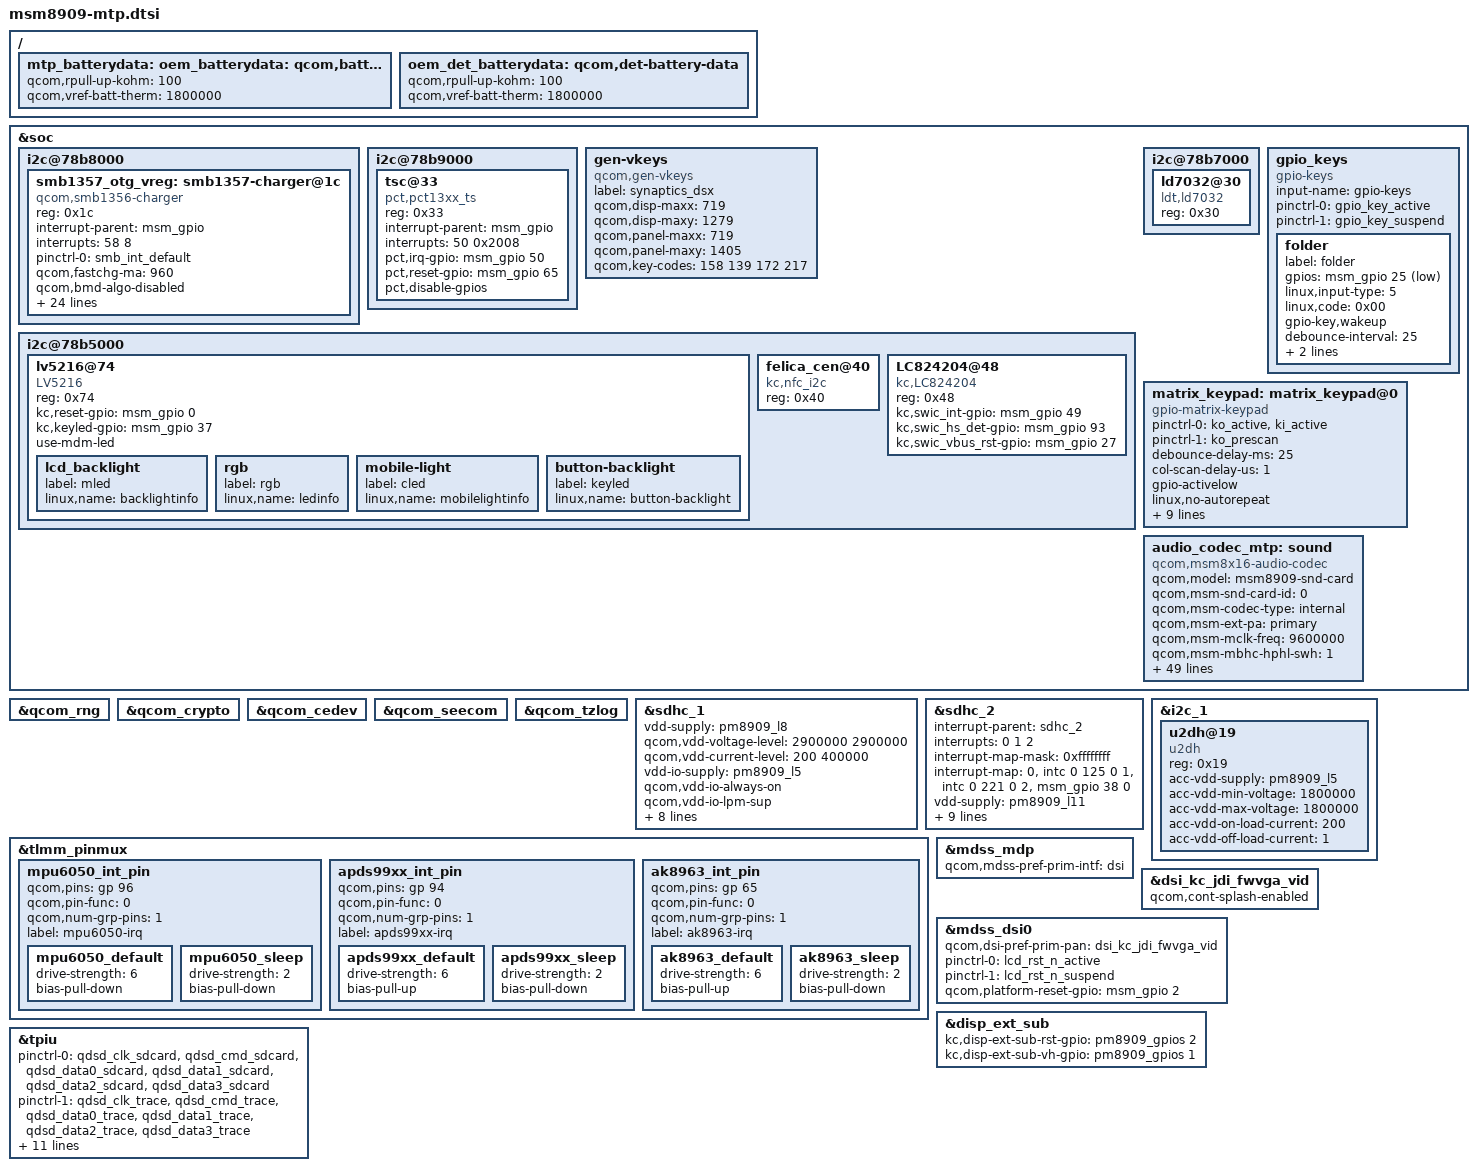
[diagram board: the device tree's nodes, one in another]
/* Copyright (c) 2014-2015, The Linux Foundation. All rights reserved.
 *
 * This program is free software; you can redistribute it and/or modify
 * it under the terms of the GNU General Public License version 2 and
 * only version 2 as published by the Free Software Foundation.
 *
 * This program is distributed in the hope that it will be useful,
 * but WITHOUT ANY WARRANTY; without even the implied warranty of
 * MERCHANTABILITY or FITNESS FOR A PARTICULAR PURPOSE.  See the
 * GNU General Public License for more details.
 */
/*
 * This software is contributed or developed by KYOCERA Corporation.
 * (C) 2016 KYOCERA Corporation
 */

#include "msm8909.dtsi"
#include "msm8909-pinctrl.dtsi"
#include "msm8909-camera-sensor-mtp.dtsi"
#include "msm8909-pm8916.dtsi"

&soc {
	/*
	 * DT node to add support for SMB135x charger and integrate
	 * with VM-BMS.
	 */
	i2c@78b8000 {
		smb1357_otg_vreg: smb1357-charger@1c {
			compatible = "qcom,smb1356-charger";
			reg = <0x1c>;
			interrupt-parent = <&msm_gpio>;
			interrupts = <58 8>;
			pinctrl-names = "default";
			pinctrl-0 = <&smb_int_default>;

			qcom,fastchg-ma = <960>;
			qcom,bmd-algo-disabled;
			qcom,float-voltage-mv = <4300>;
			qcom,charging-timeout = <768>;
			qcom,recharge-thresh-mv = <200>;
			qcom,thermal-mitigation = <960 540 180 0>;

			qcom,bms-psy-name = "bms";

			/*
			 * JEITA
			 */
			qcom,gamma-setting = <2 3 0 3>;

			/*
			 * Enable SMB1357 based charging termination as BMS
			 * controls charging.
			 */
			qcom,iterm-ma = <100>;
			

			/*
			 * Disable charge inhibit feature to start chargin on
			 * charger insertion independent of battery voltage.
			 */
			qcom,inhibit-disabled;

			/* BMS is controlling charging/re-charge */
			//	qcom,bms-controlled-charging;

			/*
			 * To enable charger node:
			 * set status = "ok" and
			 * add 'qcom,use-external-charger' to pm8909_chg node
			 */
			status = "ok";

			/*
			 * For DC charging support
			 */
			qcom,dc-psy-type = "Mains";
			qcom,dc-psy-ma = <960>;

			/*
			 * SW_JEITA
			 */
			qcom,soft-vfloat-comp-disabled;
			qcom,soft-current-comp-disabled;
			qcom,chg-vadc = <&pm8916_vadc>;
			qcom,chg-adc_tm = <&pm8916_adc_tm>;
			qcom,hot-bat-decidegc = <500>;
			qcom,cold-bat-decidegc = <0>;
			qcom,bat-present-decidegc = <300>;
			qcom,warm-bat-decidegc = <450>;
			qcom,cool-bat-decidegc = <100>;
			qcom,warm-bat-ma = <420>;
			qcom,cool-bat-ma = <420>;
			qcom,warm-bat-mv = <4200>;
			qcom,cool-bat-mv = <4200>;

			/*
			 * Voltage at the time of battery deterioration
			 */
			oem,deterioration-vfloat-mv = <4200>;
		};
	};

	i2c@78b9000 { /* BLSP1 QUP5 */
		tsc@33 {
			compatible = "pct,pct13xx_ts";
			reg = <0x33>;
			interrupt-parent = <&msm_gpio>;
			interrupts = <50 0x2008>;
			pct,irq-gpio = <&msm_gpio 50 0x2008>;
			pct,reset-gpio = <&msm_gpio 65 0x0>;
			pct,disable-gpios;
		};
	};

	gen-vkeys {
		compatible = "qcom,gen-vkeys";
		label = "synaptics_dsx";
		qcom,disp-maxx = <719>;
		qcom,disp-maxy = <1279>;
		qcom,panel-maxx = <719>;
		qcom,panel-maxy = <1405>;
		qcom,key-codes = <158 139 172 217>;
	};

//	i2c@78b6000 { /* BLSP1 QUP2 */
//		nfc-nci@e {
//			compatible = "qcom,nfc-nci";
//			reg = <0x0e>;
//			qcom,irq-gpio = <&msm_gpio 21 0x00>;
//			qcom,dis-gpio = <&msm_gpio 20 0x00>;
//			qcom,clk-src = "BBCLK2";
//			interrupt-parent = <&msm_gpio>;
//			interrupts = <21 0>;
//			interrupt-names = "nfc_irq";
//			pinctrl-names = "nfc_active","nfc_suspend";
//			pinctrl-0 = <&nfc_int_active &nfc_disable_active>;
//			pinctrl-1 = <&nfc_int_suspend &nfc_disable_suspend>;
//			clocks = <&clock_rpm clk_bb_clk2_pin>;
//			clock-names = "ref_clk";
//		};
//
//		nq@2b {
//			compatible = "qcom,nq-nci";
//			reg = <0x2b>;
//			qcom,nq-irq = <&msm_gpio 21 0x00>;
//			qcom,nq-ven = <&msm_gpio 20 0x00>;
//			qcom,nq-firm = <&msm_gpio 45 0x00>;
//			qcom,clk-src = "BBCLK2";
//			interrupt-parent = <&msm_gpio>;
//			interrupts = <21 0>;
//			interrupt-names = "nfc_irq";
//			pinctrl-names = "nfc_active","nfc_suspend";
//			pinctrl-0 = <&nfc_int_active &nfc_disable_active>;
//			pinctrl-1 = <&nfc_int_suspend &nfc_disable_suspend>;
//			clocks = <&clock_rpm clk_bb_clk2_pin>;
//			clock-names = "ref_clk";
//			};
//	};

	i2c@78b5000 {
		lv5216@74 {
			compatible = "LV5216";
			reg = <0x74>;
			kc,reset-gpio = <&msm_gpio 0 0x00>;
			kc,keyled-gpio = <&msm_gpio 37 0x00>;
			use-mdm-led;
			lcd_backlight {
				label = "mled";
				linux,name = "backlightinfo";
			};
			rgb {
				label = "rgb";
				linux,name = "ledinfo";
			};
			mobile-light {
				label = "cled";
				linux,name = "mobilelightinfo";
			};
			button-backlight {
				label = "keyled";
				linux,name = "button-backlight";
			};
		};
	};
	i2c@78b5000 {
		felica_cen@40 {
			status = "okay";
			compatible = "kc,nfc_i2c";
			reg = <0x40>;
		};
	};

	i2c@78b5000 {
		LC824204@48 {
			status = "okay";
			compatible = "kc,LC824204";
			reg = <0x48>;
			kc,swic_int-gpio = <&msm_gpio 49 0>;
			kc,swic_hs_det-gpio = <&msm_gpio 93 0>;
			kc,swic_vbus_rst-gpio = <&msm_gpio 27 0>;
		};
	};

	i2c@78b7000 {
		ld7032@30 {
			compatible = "ldt,ld7032";
			reg = <0x30>;
		};
	};

	gpio_keys {
		compatible = "gpio-keys";
		input-name = "gpio-keys";
		pinctrl-names = "tlmm_gpio_key_active","tlmm_gpio_key_suspend";
		pinctrl-0 = <&gpio_key_active>;
		pinctrl-1 = <&gpio_key_suspend>;

		//camera_focus {
		//	label = "camera_focus";
		//	gpios = <&msm_gpio 91 0x1>;
		//	linux,input-type = <1>;
		//	linux,code = <0x210>;
		//	gpio-key,wakeup;
		//	debounce-interval = <15>;
		//};

		//camera_snapshot {
		//	label = "camera_snapshot";
		//	gpios = <&msm_gpio 92 0x1>;
		//	linux,input-type = <1>;
		//	linux,code = <0x2fe>;
		//	gpio-key,wakeup;
		//	debounce-interval = <15>;
		//};

		//vol_up {
		//	label = "volume_up";
		//	gpios = <&msm_gpio 90 0x1>;
		//	linux,input-type = <1>;
		//	linux,code = <115>;
		//	gpio-key,wakeup;
		//	debounce-interval = <15>;
		//};

		folder {
			label = "folder";
			gpios =  <&msm_gpio 25 0x1>;
			linux,input-type = <5>;
			linux,code = <0x00>;
			gpio-key,wakeup;
			debounce-interval = <25>;
            on_chattering_num  = <1>;
            off_chattering_num = <1>;
		};

	};

	matrix_keypad: matrix_keypad@0 {
		compatible = "gpio-matrix-keypad";
		pinctrl-names = "matrix_keypad_active","matrix_keypad_prescan";
		pinctrl-0 = <&ko_active &ki_active>;
		pinctrl-1 = <&ko_prescan>;
		debounce-delay-ms = <25>;
		col-scan-delay-us = <1>;
		gpio-activelow;
		linux,no-autorepeat;
		linux,wakeup;

		row-gpios = <
			&msm_gpio 94 0
			&msm_gpio 95 0
			&msm_gpio 96 0
			&msm_gpio 97 0
			&msm_gpio 98 0
			&msm_gpio 91 0
		>;

		col-gpios = <
			&msm_gpio 16 0
			&msm_gpio 17 0
			&msm_gpio 34 0
			&msm_gpio 57 0
			&msm_gpio 92 0
			&msm_gpio  3 0
			&msm_gpio 28 0
			&msm_gpio 33 0
		>;

		linux,keymap = <
			0x00000002	/* KEY_1 [2] */
			0x00010005	/* KEY_4 [5] */
			0x00020008	/* KEY_7 [8] */
			0x00030037	/* KEY_KPASTERISK [55]*/
			0x0004003E	/* KEY_F4 [62] */
			0x01000003	/* KEY_2 [3] */
			0x01010006	/* KEY_5 [6] */
			0x01020009	/* KEY_8 [9] */
			0x0103000b	/* KEY_0 [11]*/
			0x0104003d	/* KEY_F3 [61] */
			0x02000004	/* KEY_3 [4] */
			0x02010007	/* KEY_6 [7] */
			0x0202000a	/* KEY_9 [10] */
			0x020300FD	/* KEY_SHARP [253] */
			0x02040163	/* KEY_CLEAR [0x163] */
			0x0305001C	/* KEY_ENTER [28] */
			0x03060067	/* KEY_UP [103] */
			0x0307006A	/* KEY_RIGHT [106] */
			0x04060069	/* KEY_LEFT [105] */
			0x0407006C	/* KEY_DOWN [108] */
			0x05000041	/* KEY_F7 [65] */
			0x0501003F	/* KEY_F5 [63] */
			0x05020040	/* KEY_F6 [64] */
			0x0503003B	/* KEY_F1 [59] */
			0x050400E7	/* KEY_SEND [231] */
			0x0505003C	/* KEY_F2 [60] */
		>;
	};

	audio_codec_mtp: sound {
		compatible = "qcom,msm8x16-audio-codec";
		qcom,model = "msm8909-snd-card";
		qcom,msm-snd-card-id = <0>;
		qcom,msm-codec-type = "internal";
		qcom,msm-ext-pa = "primary";
		qcom,msm-mclk-freq = <9600000>;
		qcom,msm-mbhc-hphl-swh = <1>;
		qcom,msm-mbhc-gnd-swh = <0>;
		qcom,msm-hs-micbias-type = "internal";
		qcom,msm-micbias1-ext-cap;
		qcom,audio-routing =
			"RX_BIAS", "MCLK",
			"SPK_RX_BIAS", "MCLK",
			"INT_LDO_H", "MCLK",
            "Rcv amp", "EAR",
			"MIC BIAS External", "Handset Mic",
			"MIC BIAS Internal2", "Headset Mic",
			"MIC BIAS External", "Secondary Mic",
			"AMIC1", "MIC BIAS External",
			"AMIC2", "MIC BIAS Internal2",
			"AMIC3", "MIC BIAS External";
		pinctrl-names = "cdc_lines_act",
				"cdc_lines_sus",
				"cross_conn_det_act",
				"cross_conn_det_sus";
		pinctrl-0 = <&cdc_pdm_lines_act>;
		pinctrl-1 = <&cdc_pdm_lines_sus>;
		pinctrl-2 = <&cross_conn_det_act>;
		pinctrl-3 = <&cross_conn_det_sus>;
//		qcom,cdc-us-euro-gpios = <&msm_gpio 97 0>;
		asoc-platform = <&pcm0>, <&pcm1>, <&voip>, <&voice>,
				<&loopback>, <&compress>, <&hostless>,
				<&afe>, <&lsm>, <&routing>, <&lpa>,
				<&voice_svc>;
		asoc-platform-names = "msm-pcm-dsp.0", "msm-pcm-dsp.1",
				"msm-voip-dsp", "msm-pcm-voice", "msm-pcm-loopback",
				"msm-compress-dsp", "msm-pcm-hostless", "msm-pcm-afe",
				"msm-lsm-client", "msm-pcm-routing", "msm-pcm-lpa",
				"msm-voice-svc";
		asoc-cpu = <&dai_pri_auxpcm>, <&dai_hdmi>,
				<&dai_mi2s0>, <&dai_mi2s1>, <&dai_mi2s2>, <&dai_mi2s3>,
				<&sb_0_rx>, <&sb_0_tx>, <&sb_1_rx>, <&sb_1_tx>,
				<&sb_3_rx>, <&sb_3_tx>, <&sb_4_rx>, <&sb_4_tx>,
				<&bt_sco_rx>, <&bt_sco_tx>, <&int_fm_rx>, <&int_fm_tx>,
				<&afe_pcm_rx>, <&afe_pcm_tx>, <&afe_proxy_rx>, <&afe_proxy_tx>,
				<&incall_record_rx>, <&incall_record_tx>, <&incall_music_rx>,
				<&incall_music_2_rx>;
		asoc-cpu-names = "msm-dai-q6-auxpcm.1", "msm-dai-q6-hdmi.8",
				"msm-dai-q6-mi2s.0", "msm-dai-q6-mi2s.1",
				"msm-dai-q6-mi2s.2", "msm-dai-q6-mi2s.3",
				"msm-dai-q6-dev.16384", "msm-dai-q6-dev.16385",
				"msm-dai-q6-dev.16386", "msm-dai-q6-dev.16387",
				"msm-dai-q6-dev.16390", "msm-dai-q6-dev.16391",
				"msm-dai-q6-dev.16392", "msm-dai-q6-dev.16393",
				"msm-dai-q6-dev.12288", "msm-dai-q6-dev.12289",
				"msm-dai-q6-dev.12292", "msm-dai-q6-dev.12293",
				"msm-dai-q6-dev.224", "msm-dai-q6-dev.225",
				"msm-dai-q6-dev.241", "msm-dai-q6-dev.240",
				"msm-dai-q6-dev.32771", "msm-dai-q6-dev.32772",
				"msm-dai-q6-dev.32773", "msm-dai-q6-dev.32770";
		asoc-codec = <&stub_codec>, <&pm8909_conga_dig>;
		asoc-codec-names = "msm-stub-codec.1", "tombak_codec";
		kc,rcv-amp-gpio-ctrl = <&msm_gpio 24 0>;
	};
};

/ {
	mtp_batterydata: qcom,battery-data {
		qcom,rpull-up-kohm = <100>;
		qcom,vref-batt-therm = <1800000>;

		#include "batterydata-palladium.dtsi"
	};
};

/ {
	oem_batterydata: qcom,battery-data {
		qcom,rpull-up-kohm = <100>;
		qcom,vref-batt-therm = <1800000>;

		#include "batterydata-oem.dtsi"
	};
};

/ {
	oem_det_batterydata: qcom,det-battery-data {
		qcom,rpull-up-kohm = <100>;
		qcom,vref-batt-therm = <1800000>;

		#include "batterydata-oem-det.dtsi"
	};
};

&qcom_rng {
	status = "okay";
};

&qcom_crypto {
	status = "okay";
};

&qcom_cedev {
	status = "okay";
};

&qcom_seecom {
	status = "okay";
};

&qcom_tzlog {
	status = "okay";
};

&sdhc_1 {
	vdd-supply = <&pm8909_l8>;
	qcom,vdd-voltage-level = <2900000 2900000>;
	qcom,vdd-current-level = <200 400000>;

	vdd-io-supply = <&pm8909_l5>;
	qcom,vdd-io-always-on;
	qcom,vdd-io-lpm-sup;
	qcom,vdd-io-voltage-level = <1800000 1800000>;
	qcom,vdd-io-current-level = <200 60000>;

	pinctrl-names = "active", "sleep";
	pinctrl-0 = <&sdc1_clk_on &sdc1_cmd_on &sdc1_data_on>;
	pinctrl-1 = <&sdc1_clk_off &sdc1_cmd_off &sdc1_data_off>;

	qcom,bus-speed-mode = "HS200_1p8v", "DDR_1p8v";
	qcom,nonremovable;

	status = "ok";
};

&sdhc_2 {
	 #address-cells = <0>;
	interrupt-parent = <&sdhc_2>;
	interrupts = <0 1 2>;
	#interrupt-cells = <1>;
	interrupt-map-mask = <0xffffffff>;
	interrupt-map = <0 &intc 0 125 0
			1 &intc 0 221 0
			2 &msm_gpio 38 0>;
	interrupt-names = "hc_irq", "pwr_irq", "status_irq";
	/* cd-gpios = <&msm_gpio 38 0x1>; */

	vdd-supply = <&pm8909_l11>;
	qcom,vdd-voltage-level = <1800000 2950000>;
	qcom,vdd-current-level = <15000 400000>;

	vdd-io-supply = <&pm8909_l12>;
	qcom,vdd-io-voltage-level = <1800000 2950000>;
	qcom,vdd-io-current-level = <200 50000>;

	pinctrl-names = "active", "sleep";
	pinctrl-0 = <&sdc2_clk_on &sdc2_cmd_on &sdc2_data_on >;
	pinctrl-1 = <&sdc2_clk_off &sdc2_cmd_off &sdc2_data_off >;

	status = "ok";
};

&tlmm_pinmux {
	mpu6050_int_pin {
		qcom,pins = <&gp 96>;
		qcom,pin-func = <0>;
		qcom,num-grp-pins = <1>;
		label = "mpu6050-irq";
		mpu6050_default: mpu6050_default {
			drive-strength = <6>;
			bias-pull-down;
		};
		mpu6050_sleep: mpu6050_sleep {
			drive-strength = <2>;
			bias-pull-down;
		};
	};

	apds99xx_int_pin {
		qcom,pins = <&gp 94>;
		qcom,pin-func = <0>;
		qcom,num-grp-pins = <1>;
		label = "apds99xx-irq";
		apds99xx_default: apds99xx_default {
			drive-strength = <6>;
			bias-pull-up;
		};
		apds99xx_sleep: apds99xx_sleep {
			drive-strength = <2>;
			bias-pull-down;
		};
	};

	ak8963_int_pin {
		qcom,pins = <&gp 65>;
		qcom,pin-func = <0>;
		qcom,num-grp-pins = <1>;
		label = "ak8963-irq";
		ak8963_default: ak8963_default {
			drive-strength = <6>;
			bias-pull-up;
		};
		ak8963_sleep: ak8963_sleep {
			drive-strength = <2>;
			bias-pull-down;
		};
	};
};

&i2c_1 { /* BLSP1 QUP1 */
u2dh@19 { /* Accelerometer sensor */
		compatible = "u2dh";
		reg = <0x19>;
		acc-vdd-supply = <&pm8909_l5>;
		acc-vdd-min-voltage = <1800000>;
		acc-vdd-max-voltage = <1800000>;
		acc-vdd-on-load-current = <200>;
		acc-vdd-off-load-current = <1>;
	};
};

#include "dsi-panel-kc-jdi-fwvga-video.dtsi"

&mdss_mdp {
	qcom,mdss-pref-prim-intf = "dsi";
};

&dsi_kc_jdi_fwvga_vid {
	qcom,cont-splash-enabled;
};

&mdss_dsi0 {
	qcom,dsi-pref-prim-pan = <&dsi_kc_jdi_fwvga_vid>;
	pinctrl-names = "mdss_default", "mdss_sleep";
	pinctrl-0 = <&lcd_rst_n_active>;
	pinctrl-1 = <&lcd_rst_n_suspend>;

	qcom,platform-reset-gpio = <&msm_gpio 2 0>;
};

#include "panel-kc-pioneer-092inch.dtsi"

&disp_ext_sub {
	kc,disp-ext-sub-rst-gpio = <&pm8909_gpios 2 0>;
	kc,disp-ext-sub-vh-gpio = <&pm8909_gpios 1 0>;
};

/* CoreSight */
&tpiu {
	pinctrl-names = "sdcard", "trace", "swduart",
			"swdtrc", "jtag", "spmi";
	/* NIDnT */
	pinctrl-0 = <&qdsd_clk_sdcard &qdsd_cmd_sdcard
		     &qdsd_data0_sdcard &qdsd_data1_sdcard
		     &qdsd_data2_sdcard &qdsd_data3_sdcard>;
	pinctrl-1 = <&qdsd_clk_trace &qdsd_cmd_trace
		     &qdsd_data0_trace &qdsd_data1_trace
		     &qdsd_data2_trace &qdsd_data3_trace>;
	pinctrl-2 = <&qdsd_cmd_swduart &qdsd_data0_swduart
		     &qdsd_data1_swduart &qdsd_data2_swduart
		     &qdsd_data3_swduart>;
	pinctrl-3 = <&qdsd_clk_swdtrc &qdsd_cmd_swdtrc
		     &qdsd_data0_swdtrc &qdsd_data1_swdtrc
		     &qdsd_data2_swdtrc &qdsd_data3_swdtrc>;
	pinctrl-4 = <&qdsd_cmd_jtag &qdsd_data0_jtag
		     &qdsd_data1_jtag &qdsd_data2_jtag
		     &qdsd_data3_jtag>;
	pinctrl-5 = <&qdsd_clk_spmi &qdsd_cmd_spmi
		     &qdsd_data0_spmi &qdsd_data3_spmi>;
};
